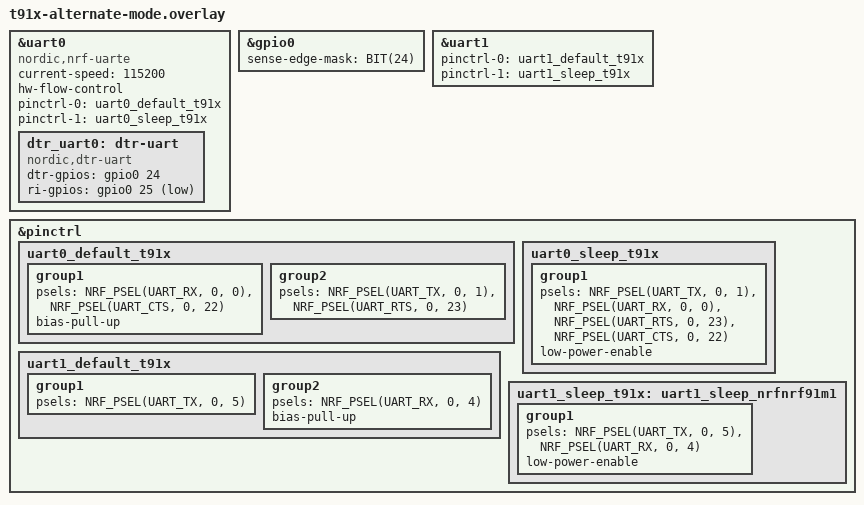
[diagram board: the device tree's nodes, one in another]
/*
 * Copyright (c) 2026 Nordic Semiconductor ASA
 *
 * SPDX-License-Identifier: LicenseRef-Nordic-5-Clause
 */

/* AT command UART */
&uart0 {
	compatible = "nordic,nrf-uarte";
	current-speed = <115200>;
	hw-flow-control;
	status = "okay";

	dtr_uart0: dtr-uart {
		compatible = "nordic,dtr-uart";
		dtr-gpios = <&gpio0 24 (GPIO_PULL_UP | GPIO_ACTIVE_HIGH)>; /* shared GPIO3 */
		ri-gpios = <&gpio0 25 GPIO_ACTIVE_LOW>; /* shared GPIO4 */
		status = "okay";
	};
	pinctrl-0 = <&uart0_default_t91x>;
	pinctrl-1 = <&uart0_sleep_t91x>;
	pinctrl-names = "default", "sleep";
};

&gpio0 {
	status = "okay";
	/* Use PORT event for DTR (24) pin to save power */
	sense-edge-mask = <BIT(24)>;
};

/* Log / Trace UART */
&uart1 {
	pinctrl-0 = <&uart1_default_t91x>;
	pinctrl-1 = <&uart1_sleep_t91x>;
	pinctrl-names = "default", "sleep";
};

&pinctrl {
	uart0_default_t91x: uart0_default_t91x {
		group1 {
			psels = <NRF_PSEL(UART_RX, 0, 0)>, /* default t91x UART0_RX */
				<NRF_PSEL(UART_CTS, 0, 22)>; /* shared GPIO1 */
			bias-pull-up;
		};
		group2 {
			psels = <NRF_PSEL(UART_TX, 0, 1)>, /* default t91x UART0_TX */
				<NRF_PSEL(UART_RTS, 0, 23)>; /* shared GPIO2 */
		};
	};

	uart0_sleep_t91x: uart0_sleep_t91x {
		group1 {
			psels = <NRF_PSEL(UART_TX, 0, 1)>,
				<NRF_PSEL(UART_RX, 0, 0)>,
				<NRF_PSEL(UART_RTS, 0, 23)>,
				<NRF_PSEL(UART_CTS, 0, 22)>;
			low-power-enable;
		};
	};

	uart1_default_t91x: uart1_default_t91x {
		group1 {
			psels = <NRF_PSEL(UART_TX, 0, 5)>;
		};

		group2 {
			psels = <NRF_PSEL(UART_RX, 0, 4)>;
			bias-pull-up;
		};
	};

	uart1_sleep_t91x: uart1_sleep_nrfnrf91m1 {
		group1 {
			psels = <NRF_PSEL(UART_TX, 0, 5)>,
				<NRF_PSEL(UART_RX, 0, 4)>;
			low-power-enable;
		};
	};
};
